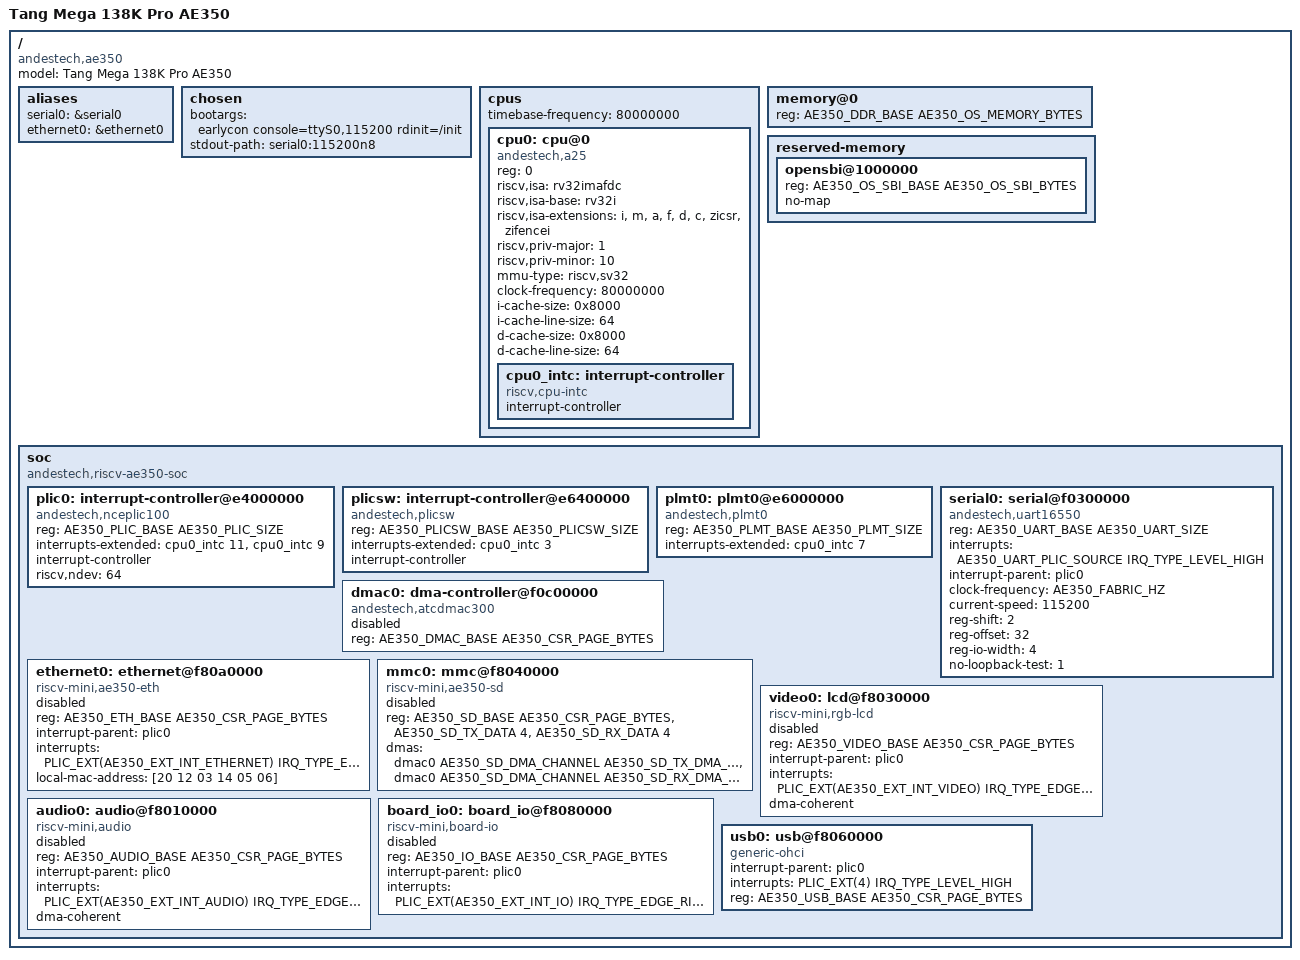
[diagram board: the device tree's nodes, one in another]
// SPDX-License-Identifier: GPL-2.0+
/*
 * Device Tree Source for Tang Mega 138K Pro (Andes AE350 SoC)
 *
 * C-preprocessed with the header generated from address_map.py. Node unit
 * addresses must match their reg; the build runs dtc with that check as error.
 */

/dts-v1/;
#include "ae350_dts.h"

#define PLIC_EXT(n) (AE350_PLIC_EXT_INT_SOURCE_BASE + (n))
#define IRQ_TYPE_EDGE_RISING 1
#define IRQ_TYPE_LEVEL_HIGH 4

/ {
	#address-cells = <1>;
	#size-cells = <1>;
	model = "Tang Mega 138K Pro AE350";
	compatible = "andestech,ae350", "riscv-mini,mega138k_ae350";

	aliases {
		serial0 = &serial0;
		ethernet0 = &ethernet0;
	};

	chosen {
		bootargs = "earlycon console=ttyS0,115200 rdinit=/init";
		stdout-path = "serial0:115200n8";
	};

	cpus {
		#address-cells = <1>;
		#size-cells = <0>;
		timebase-frequency = <80000000>;

		cpu0: cpu@0 {
			device_type = "cpu";
			reg = <0>;
			status = "okay";
			compatible = "andestech,a25", "riscv";
			riscv,isa = "rv32imafdc";
			riscv,isa-base = "rv32i";
			riscv,isa-extensions = "i", "m", "a", "f", "d", "c", "zicsr", "zifencei";
			riscv,priv-major = <1>;
			riscv,priv-minor = <10>;
			mmu-type = "riscv,sv32";
			clock-frequency = <80000000>;
			i-cache-size = <0x8000>;
			i-cache-line-size = <64>;
			d-cache-size = <0x8000>;
			d-cache-line-size = <64>;

			cpu0_intc: interrupt-controller {
				#interrupt-cells = <1>;
				interrupt-controller;
				compatible = "riscv,cpu-intc";
			};
		};
	};

	memory@0 {
		device_type = "memory";
		reg = <AE350_DDR_BASE AE350_OS_MEMORY_BYTES>;
	};

	reserved-memory {
		#address-cells = <1>;
		#size-cells = <1>;
		ranges;

		opensbi@1000000 {
			reg = <AE350_OS_SBI_BASE AE350_OS_SBI_BYTES>;
			no-map;
		};
	};

	soc {
		#address-cells = <1>;
		#size-cells = <1>;
		compatible = "andestech,riscv-ae350-soc", "simple-bus";
		ranges;

		plic0: interrupt-controller@e4000000 {
			compatible = "andestech,nceplic100", "riscv,plic0";
			reg = <AE350_PLIC_BASE AE350_PLIC_SIZE>;
			interrupts-extended = <&cpu0_intc 11>, <&cpu0_intc 9>;
			interrupt-controller;
			#interrupt-cells = <2>;
			riscv,ndev = <64>;
		};

		plicsw: interrupt-controller@e6400000 {
			compatible = "andestech,plicsw";
			reg = <AE350_PLICSW_BASE AE350_PLICSW_SIZE>;
			interrupts-extended = <&cpu0_intc 3>;
			interrupt-controller;
			#interrupt-cells = <1>;
		};

		plmt0: plmt0@e6000000 {
			compatible = "andestech,plmt0";
			reg = <AE350_PLMT_BASE AE350_PLMT_SIZE>;
			interrupts-extended = <&cpu0_intc 7>;
		};

		serial0: serial@f0300000 {
			compatible = "andestech,uart16550", "ns16550a";
			reg = <AE350_UART_BASE AE350_UART_SIZE>;
			interrupts = <AE350_UART_PLIC_SOURCE IRQ_TYPE_LEVEL_HIGH>;
			interrupt-parent = <&plic0>;
			clock-frequency = <AE350_FABRIC_HZ>;
			current-speed = <115200>;
			reg-shift = <2>;
			reg-offset = <32>;
			reg-io-width = <4>;
			no-loopback-test = <1>;
		};

		dmac0: dma-controller@f0c00000 {
			compatible = "andestech,atcdmac300";
			reg = <AE350_DMAC_BASE AE350_CSR_PAGE_BYTES>;
			#dma-cells = <2>;	/* channel, request selector */
			status = "disabled";
		};

		/* Linux has no driver for the AE350 SD and Ethernet blocks; U-Boot enables them. */
		ethernet0: ethernet@f80a0000 {
			compatible = "riscv-mini,ae350-eth";
			reg = <AE350_ETH_BASE AE350_CSR_PAGE_BYTES>;
			interrupt-parent = <&plic0>;
			interrupts = <PLIC_EXT(AE350_EXT_INT_ETHERNET) IRQ_TYPE_EDGE_RISING>;
			status = "disabled";
			local-mac-address = [20 12 03 14 05 06];
		};

		mmc0: mmc@f8040000 {
			compatible = "riscv-mini,ae350-sd";
			reg = <AE350_SD_BASE AE350_CSR_PAGE_BYTES>,
			      <AE350_SD_TX_DATA 4>, <AE350_SD_RX_DATA 4>;
			reg-names = "core", "tx", "rx";
			dmas = <&dmac0 AE350_SD_DMA_CHANNEL AE350_SD_TX_DMA_SEL>,
			       <&dmac0 AE350_SD_DMA_CHANNEL AE350_SD_RX_DMA_SEL>;
			dma-names = "tx", "rx";
			status = "disabled";
		};

		video0: lcd@f8030000 {
			compatible = "riscv-mini,rgb-lcd";
			reg = <AE350_VIDEO_BASE AE350_CSR_PAGE_BYTES>;
			interrupt-parent = <&plic0>;
			interrupts = <PLIC_EXT(AE350_EXT_INT_VIDEO) IRQ_TYPE_EDGE_RISING>;
			dma-coherent;
			status = "disabled";
		};

		audio0: audio@f8010000 {
			compatible = "riscv-mini,audio";
			reg = <AE350_AUDIO_BASE AE350_CSR_PAGE_BYTES>;
			interrupt-parent = <&plic0>;
			interrupts = <PLIC_EXT(AE350_EXT_INT_AUDIO) IRQ_TYPE_EDGE_RISING>;
			dma-coherent;
			status = "disabled";
		};

		board_io0: board_io@f8080000 {
			compatible = "riscv-mini,board-io";
			reg = <AE350_IO_BASE AE350_CSR_PAGE_BYTES>;
			interrupt-parent = <&plic0>;
			interrupts = <PLIC_EXT(AE350_EXT_INT_IO) IRQ_TYPE_EDGE_RISING>;
			status = "disabled";
		};

		/* OHCI DMA host, fabric EXT_INT[4]. */
		usb0: usb@f8060000 {
			compatible = "generic-ohci";
			interrupt-parent = <&plic0>;
			interrupts = <PLIC_EXT(4) IRQ_TYPE_LEVEL_HIGH>;
			reg = <AE350_USB_BASE AE350_CSR_PAGE_BYTES>;
			status = "okay";
		};
	};
};
